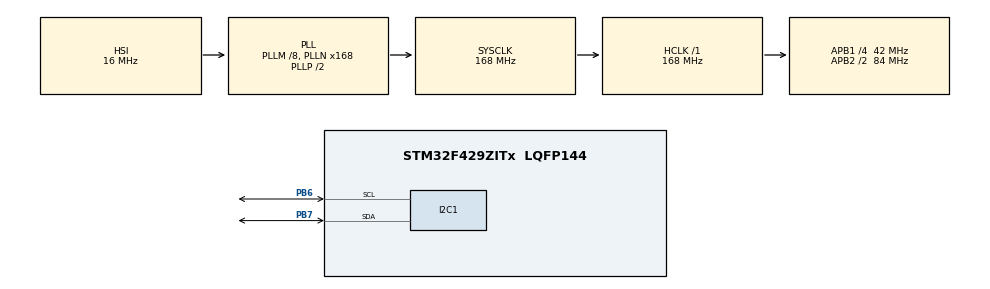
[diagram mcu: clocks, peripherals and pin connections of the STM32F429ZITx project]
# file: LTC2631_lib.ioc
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Mcu.Family=STM32F4
Mcu.Name=STM32F429ZITx
Mcu.Package=LQFP144
NVIC.PriorityGroup=NVIC_PRIORITYGROUP_4
PA13.Mode=Serial_Wire
PA13.Signal=SYS_JTMS-SWDIO
PA14.Mode=Serial_Wire
PA14.Signal=SYS_JTCK-SWCLK
PB6.Mode=I2C
PB6.Signal=I2C1_SCL
PB7.Mode=I2C
PB7.Signal=I2C1_SDA
PH0/OSC_IN.Mode=HSE-External-Oscillator
PH0/OSC_IN.Signal=RCC_OSC_IN
PH1/OSC_OUT.Mode=HSE-External-Oscillator
PH1/OSC_OUT.Signal=RCC_OSC_OUT
ProjectManager.HeapSize=0x200
ProjectManager.StackSize=0x400
ProjectManager.TargetToolchain=STM32CubeIDE
RCC.48MHZClocksFreq_Value=84000000
RCC.AHBFreq_Value=168000000
RCC.APB1CLKDivider=RCC_HCLK_DIV4
RCC.APB1Freq_Value=42000000
RCC.APB1TimFreq_Value=84000000
RCC.APB2CLKDivider=RCC_HCLK_DIV2
RCC.APB2Freq_Value=84000000
RCC.APB2TimFreq_Value=168000000
RCC.CortexFreq_Value=168000000
RCC.HCLKFreq_Value=168000000
RCC.HSE_VALUE=25000000
RCC.HSI_VALUE=16000000
RCC.LSE_VALUE=32768
RCC.PLLM=8
RCC.PLLN=168
RCC.SYSCLKFreq_VALUE=168000000
RCC.SYSCLKSource=RCC_SYSCLKSOURCE_PLLCLK
RCC.VCOOutputFreq_Value=336000000
board=custom

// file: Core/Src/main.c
/* USER CODE BEGIN Header */
/**
  ******************************************************************************
  * @file           : main.c
  * @brief          : Main program body
  ******************************************************************************
  * @attention
  *
  * Copyright (c) 2026 STMicroelectronics.
  * All rights reserved.
  *
  * This software is licensed under terms that can be found in the LICENSE file
  * in the root directory of this software component.
  * If no LICENSE file comes with this software, it is provided AS-IS.
  *
  ******************************************************************************
  */
/* USER CODE END Header */
#include "main.h"
#include "LTC2631_lib.h"

I2C_HandleTypeDef hi2c1;
/* USER CODE BEGIN PV */
LTC2631_HandleTypeDef myDac;
/* USER CODE END PV */

void SystemClock_Config(void);
static void MX_GPIO_Init(void);
static void MX_I2C1_Init(void);

int main(void)
{

  /* USER CODE BEGIN 1 */
//global adrestanımlandı datasheetten ca1 ve ca2 nin donanımsal durumlarına göre adres değiştirilir
uint8_t dac_address = (0x73 << 1);
  /* USER CODE END 1 */

  /* MCU Configuration--------------------------------------------------------*/

  /* Reset of all peripherals, Initializes the Flash interface and the Systick. */
  HAL_Init();

  /* USER CODE BEGIN Init */
if (LTC2631_Init(&myDac, &hi2c1, dac_address) != HAL_OK)
{
	Error_Handler();
}
  /* USER CODE END Init */

  /* Configure the system clock */
  SystemClock_Config();

  /* Initialize all configured peripherals */
  MX_GPIO_Init();
  MX_I2C1_Init();
  /* USER CODE BEGIN 2 */
//çıkış gerilimini 2.5V ayarla(referans değeri entegre parça koduna göre belirlendiğinden buradaki değerler örnek olarak yazıldı)
LTC2631_SetVoltage(&myDac, 2.5f, 3.3f);
  /* USER CODE END 2 */

  /* Infinite loop */
  while (1)
  {

  }
}

void SystemClock_Config(void)
{
  RCC_OscInitTypeDef RCC_OscInitStruct = {0};
  RCC_ClkInitTypeDef RCC_ClkInitStruct = {0};

  /** Configure the main internal regulator output voltage
  */
  __HAL_RCC_PWR_CLK_ENABLE();
  __HAL_PWR_VOLTAGESCALING_CONFIG(PWR_REGULATOR_VOLTAGE_SCALE1);

  /** Initializes the RCC Oscillators according to the specified parameters
  * in the RCC_OscInitTypeDef structure.
  */
  RCC_OscInitStruct.OscillatorType = RCC_OSCILLATORTYPE_HSI;
  RCC_OscInitStruct.HSIState = RCC_HSI_ON;
  RCC_OscInitStruct.HSICalibrationValue = RCC_HSICALIBRATION_DEFAULT;
  RCC_OscInitStruct.PLL.PLLState = RCC_PLL_ON;
  RCC_OscInitStruct.PLL.PLLSource = RCC_PLLSOURCE_HSI;
  RCC_OscInitStruct.PLL.PLLM = 8;
  RCC_OscInitStruct.PLL.PLLN = 168;
  RCC_OscInitStruct.PLL.PLLP = RCC_PLLP_DIV2;
  RCC_OscInitStruct.PLL.PLLQ = 4;
  if (HAL_RCC_OscConfig(&RCC_OscInitStruct) != HAL_OK)
  {
    Error_Handler();
  }

  /** Initializes the CPU, AHB and APB buses clocks
  */
  RCC_ClkInitStruct.ClockType = RCC_CLOCKTYPE_HCLK|RCC_CLOCKTYPE_SYSCLK
                              |RCC_CLOCKTYPE_PCLK1|RCC_CLOCKTYPE_PCLK2;
  RCC_ClkInitStruct.SYSCLKSource = RCC_SYSCLKSOURCE_PLLCLK;
  RCC_ClkInitStruct.AHBCLKDivider = RCC_SYSCLK_DIV1;
  RCC_ClkInitStruct.APB1CLKDivider = RCC_HCLK_DIV4;
  RCC_ClkInitStruct.APB2CLKDivider = RCC_HCLK_DIV2;

  if (HAL_RCC_ClockConfig(&RCC_ClkInitStruct, FLASH_LATENCY_5) != HAL_OK)
  {
    Error_Handler();
  }
}

static void MX_I2C1_Init(void)
{

  hi2c1.Instance = I2C1;
  hi2c1.Init.ClockSpeed = 100000;
  hi2c1.Init.DutyCycle = I2C_DUTYCYCLE_2;
  hi2c1.Init.OwnAddress1 = 0;
  hi2c1.Init.AddressingMode = I2C_ADDRESSINGMODE_7BIT;
  hi2c1.Init.DualAddressMode = I2C_DUALADDRESS_DISABLE;
  hi2c1.Init.OwnAddress2 = 0;
  hi2c1.Init.GeneralCallMode = I2C_GENERALCALL_DISABLE;
  hi2c1.Init.NoStretchMode = I2C_NOSTRETCH_DISABLE;
  if (HAL_I2C_Init(&hi2c1) != HAL_OK)
  {
    Error_Handler();
  }

  /** Configure Analogue filter
  */
  if (HAL_I2CEx_ConfigAnalogFilter(&hi2c1, I2C_ANALOGFILTER_ENABLE) != HAL_OK)
  {
    Error_Handler();
  }

  /** Configure Digital filter
  */
  if (HAL_I2CEx_ConfigDigitalFilter(&hi2c1, 0) != HAL_OK)
  {
    Error_Handler();
  }

}

static void MX_GPIO_Init(void)
{

  /* GPIO Ports Clock Enable */
  __HAL_RCC_GPIOH_CLK_ENABLE();
  __HAL_RCC_GPIOA_CLK_ENABLE();
  __HAL_RCC_GPIOB_CLK_ENABLE();

}

void Error_Handler(void)
{
  __disable_irq();
  while (1)
  {
  }
}
